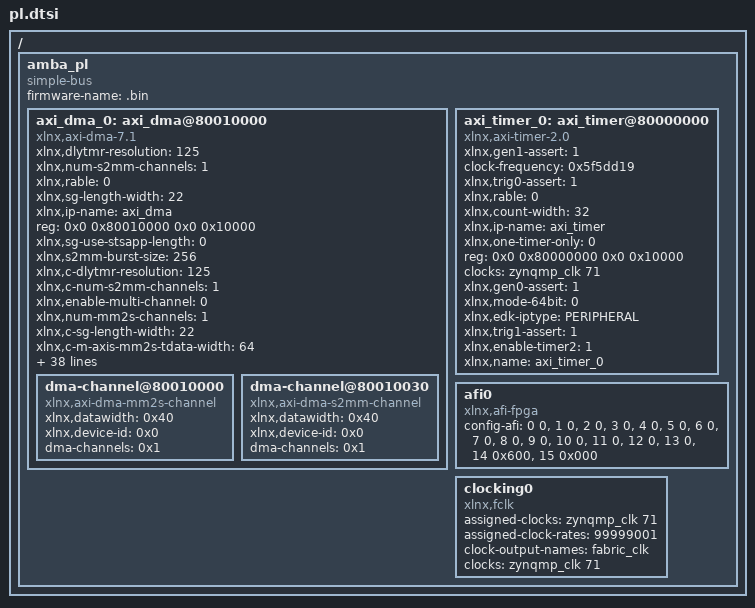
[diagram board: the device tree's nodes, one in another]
/ {
	amba_pl: amba_pl {
		ranges;
		compatible = "simple-bus";
		#address-cells = <2>;
		#size-cells = <2>;
		firmware-name = ".bin";
		axi_dma_0: axi_dma@80010000 {
			xlnx,dlytmr-resolution = <125>;
			xlnx,num-s2mm-channels = <1>;
			xlnx,rable = <0>;
			xlnx,sg-length-width = <22>;
			xlnx,ip-name = "axi_dma";
			reg = <0x0 0x80010000 0x0 0x10000>;
			xlnx,sg-use-stsapp-length = <0>;
			xlnx,s2mm-burst-size = <256>;
			xlnx,c-dlytmr-resolution = <125>;
			xlnx,c-num-s2mm-channels = <1>;
			xlnx,enable-multi-channel = <0>;
			xlnx,num-mm2s-channels = <1>;
			xlnx,c-sg-length-width = <22>;
			compatible = "xlnx,axi-dma-7.1" , "xlnx,axi-dma-1.00.a";
			xlnx,c-m-axis-mm2s-tdata-width = <64>;
			xlnx,c-sg-use-stsapp-length = <0>;
			xlnx,c-s2mm-burst-size = <256>;
			xlnx,mm2s-burst-size = <256>;
			xlnx,c-enable-multi-channel = <0>;
			xlnx,c-num-mm2s-channels = <1>;
			xlnx,include-s2mm-dre = <0>;
			xlnx,c-mm2s-burst-size = <256>;
			status = "okay";
			xlnx,c-include-s2mm-dre = <0>;
			xlnx,include-mm2s-dre = <0>;
			xlnx,name = "axi_dma_0";
			xlnx,c-include-sg = <0>;
			xlnx,c-m-axi-s2mm-data-width = <64>;
			xlnx,include-s2mm-sf = <1>;
			xlnx,c-include-mm2s-dre = <0>;
			xlnx,include-s2mm = <1>;
			clocks = <&zynqmp_clk 71>, <&zynqmp_clk 71>, <&zynqmp_clk 71>;
			xlnx,addrwidth = <0x20>;
			xlnx,c-m-axi-mm2s-data-width = <64>;
			xlnx,edk-iptype = "PERIPHERAL";
			xlnx,c-include-s2mm-sf = <1>;
			xlnx,include-mm2s-sf = <1>;
			clock-names = "m_axi_mm2s_aclk" , "m_axi_s2mm_aclk" , "s_axi_lite_aclk";
			xlnx,c-include-s2mm = <1>;
			xlnx,c-addr-width = <32>;
			xlnx,c-single-interface = <0>;
			xlnx,include-mm2s = <1>;
			xlnx,c-s-axis-s2mm-tdata-width = <64>;
			xlnx,s2mm-data-width = <0x40>;
			xlnx,c-include-mm2s-sf = <1>;
			xlnx,prmry-is-aclk-async = <0>;
			xlnx,c-include-mm2s = <1>;
			xlnx,increase-throughput = <0>;
			xlnx,micro-dma = <0>;
			xlnx,mm2s-data-width = <0x40>;
			xlnx,c-prmry-is-aclk-async = <0>;
			xlnx,c-sg-include-stscntrl-strm = <0>;
			xlnx,c-increase-throughput = <0>;
			xlnx,c-micro-dma = <0>;
			dma-channel@80010000 {
				xlnx,datawidth = <0x40>;
				xlnx,device-id = <0x0>;
				compatible = "xlnx,axi-dma-mm2s-channel";
				dma-channels = <0x1>;
			};
			dma-channel@80010030 {
				xlnx,datawidth = <0x40>;
				xlnx,device-id = <0x0>;
				compatible = "xlnx,axi-dma-s2mm-channel";
				dma-channels = <0x1>;
			};
		};
		axi_timer_0: axi_timer@80000000 {
			compatible = "xlnx,axi-timer-2.0" , "xlnx,xps-timer-1.00.a";
			xlnx,gen1-assert = <1>;
			clock-frequency = <0x5f5dd19>;
			xlnx,trig0-assert = <1>;
			xlnx,rable = <0>;
			xlnx,count-width = <32>;
			xlnx,ip-name = "axi_timer";
			xlnx,one-timer-only = <0>;
			reg = <0x0 0x80000000 0x0 0x10000>;
			clocks = <&zynqmp_clk 71>;
			xlnx,gen0-assert = <1>;
			xlnx,mode-64bit = <0>;
			xlnx,edk-iptype = "PERIPHERAL";
			xlnx,trig1-assert = <1>;
			status = "okay";
			clock-names = "s_axi_aclk";
			xlnx,enable-timer2 = <1>;
			xlnx,name = "axi_timer_0";
		};
		afi0: afi0 {
			status = "okay";
			compatible = "xlnx,afi-fpga";
			config-afi = < 0 0>, <1 0>, <2 0>, <3 0>, <4 0>, <5 0>, <6 0>, <7 0>, <8 0>, <9 0>, <10 0>, <11 0>, <12 0>, <13 0>, <14 0x600>, <15 0x000>;
		};
		clocking0: clocking0 {
			compatible = "xlnx,fclk";
			assigned-clocks = <&zynqmp_clk 71>;
			assigned-clock-rates = <99999001>;
			#clock-cells = <0>;
			clock-output-names = "fabric_clk";
			clocks = <&zynqmp_clk 71>;
		};
	};
};
